# MDR1986VE9x_BKP register map
Vendor: Milandr.; Series: ARMCM3; File version: 1.6
ARM 32-bit Cortex-M3 Microcontroller based device, CPU clock up to 80MHz, etc.
CPU: CM3 r2p1, little endian, no MPU, no FPU, 3 interrupt priority bits
Registers are 32-bit, read-write, reset 0x0 unless marked. A register's access mark holds for its fields unless they carry their own. Offsets are from the block's base; lines under a group give offsets from that group; [hi:lo] are bit positions; {n}, {i} and the like mark numbered series; 'fields as' and 'values as' point back to an identical list; <NAME> marks a mode.

## Memory map
0x400D8000 MDR_BKP size 0x54 — Backup and RTC Control

## MDR_BKP — Backup and RTC Control
Base 0x400D8000
0x00 REG_0{x} (x=0,1,2,3,4,5,6,7,8,9,A,B,C,D; step 0x4) — User backup registers
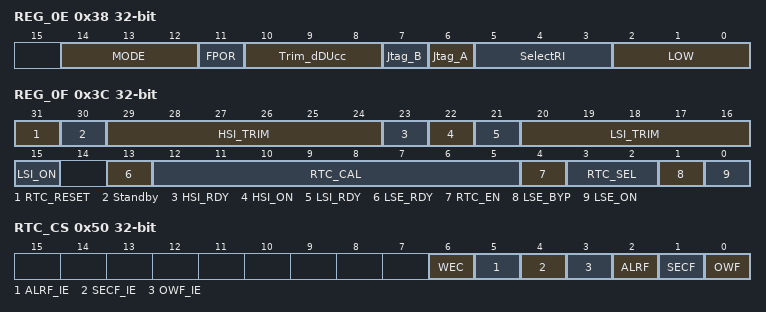
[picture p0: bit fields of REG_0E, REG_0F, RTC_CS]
0x38 REG_0E — REG_OE Control register
  [14:12] MODE — Bootloading Mode
    0=IntFlash_JtagB (Execute from internal flash with Jtag_B); 1=IntFlash_JtagA (Execute from internal flash with Jtag_A); 2=ExtMem_JtagB (Execute from external memory with Jtag_B); 3=ExtMem_JtagOff (Execute from external memory without any Jtag); 5=Uart_PD01 (Uart bootloader, pins PD[1:0]); 6=Uart_PF01 (Uart bootloader, pins PF[1:0])
  [11] FPOR — Power Reset Flag
    0=Low (No Bootloader); 1=High (Bootloader completed)
  [10:8] Trim_dDUcc — Ducc adjust voltages
    0=+0.1 (DUcc += 0.1 V); 1=+0.06 (DUcc += 0.06 V); 2=+0.04 (DUcc += 0.04 V); 3=+0.01 (DUcc += 0.01 V); 4=-0.01 (DUcc -= 0.01 V); 5=-0.04 (DUcc -= 0.04 V); 6=-0.6 (DUcc -= 0.06 V); 7=-0.1 (DUcc -= 0.1 V)
  [7] Jtag_B — Enable Jtag_B interface
    0=Disabled; 1=Enabled
  [6] Jtag_A — Enable Jtag_A interface
    0=Disabled; 1=Enabled
  [5:3] SelectRI — DUcc extra I, should be equals to LOW field!
    0=10MHz (Additional I ~ 300uA); 1=200KHz (Additional I ~ 6.6uA); 2=500KHz (Additional I ~ 20A); 3=1MHz (Additional I ~ 80uA); 4=GensOffz (Additional I ~ 2uA); 5=40MHz (Additional I ~ 900uA); 6=80MHz (Additional I ~ 4.4mA); 7=above_80MHz (Additional I ~ 19mA)
  [2:0] LOW — DUcc Freq control
    0=10MHz (CPU Clock less then 10MHz); 1=200KHz (CPU Clock less then 200KHz); 2=500KHz (CPU Clock less then 500KHz); 3=1MHz (CPU Clock less then 1MHz); 4=GensOffz (Generators Off); 5=40MHz (CPU Clock less then 40MHz); 6=80MHz (CPU Clock less then 80MHz); 7=above_80MHz (CPU Clock above 10MHz)
0x3C REG_0F — REG_OF Control register
  [31] RTC_RESET — Reset RTC bit
    0=Active (RTC active state); 1=Reset (RTC in Reset state)
  [30] Standby — Standby sleep mode
    0=Disable (Normal mode, DUcc is On); 1=Enable (Standby mode, DUcc is Off)
  [29:24] HSI_TRIM — HSI frequency adjust
  [23] HSI_RDY — HSI frequency ready
    0=NotReady (No frequency or unstable); 1=Ready (Frequency ready)
  [22] HSI_ON — HSI generator enable
    0=Off (Disable state); 1=On (Enable state)
  [21] LSI_RDY ro — LSI frequency ready
    values as HSI_RDY
  [20:16] LSI_TRIM — LSI frequency adjust
    0=69KHz (LSI frequency tuner); 1=65KHz; 2=60KHz; 3=58KHz; 4=52KHz; 5=50KHz; 6=49KHz; 7=45KHz; 8=44KHz; 9=42KHz; 10=40KHz; 11=39KHz; 12=37KHz; 13=36KHz; 14=35KHz; 15=33KHz; 16=32KHz
  [15] LSI_ON — LSI generator enable
    0=Off (Disable state); 1=On (Enable state)
  [13] LSE_RDY ro — LSE frequency ready
    values as HSI_RDY
  [12:5] RTC_CAL — RTC calibration
  [4] RTC_EN — RTC enable
    0=Off (Disable state); 1=On (Enable state)
  [3:2] RTC_SEL — Select Clock for RTC
    0=LSI (RTC use LSI clock); 1=LSE (RTC use LSE clock); 2=HSIRTC (RTC use HSIRTC clock); 3=HSERTC (RTC use HSERTC clock)
  [1] LSE_BYP — LSE generator
    0=Off (Use for external resonator); 1=On (Use for external generator)
  [0] LSE_ON — LSE generator enable
    0=Off (Disable state); 1=On (Enable state)
0x40 RTC_CNT — Count periods of PRL
0x44 RTC_DIV — Counts RTC Clock to get PRL value
  [19:0] Value — RTC DIV value
0x48 RTC_PRL — Period value for DIV counter
  [19:0] Value — RTC PRL value
0x4C RTC_ALRM — Event value for CNT counter
  [31:0] Value — Alarm value of CNT
0x50 RTC_CS — RTC Control and Status
  [6] WEC — RTC Busy flag
    0=Ready (Registers available); 1=Busy (Registers unavailable)
  [5] ALRF_IE — Enable IRQ by ALRF
    0=Off (No Event); 1=On (Event)
  [4] SECF_IE — Enable IRQ by SECF
    0=Off (No Event); 1=On (Event)
  [3] OWF_IE — Enable IRQ by OWF
    0=Off (No Event); 1=On (Event)
  [2] ALRF — CNT == ALRM Event, clear by set 1
    0=Off (No Event); 1=On (Event)
  [1] SECF — DIV == PRL Event, clear by set 1
    0=Off (No Event); 1=On (Event)
  [0] OWF — CNT Overflow flag, clear by set 1
    0=Off (No Event); 1=On (Event)
